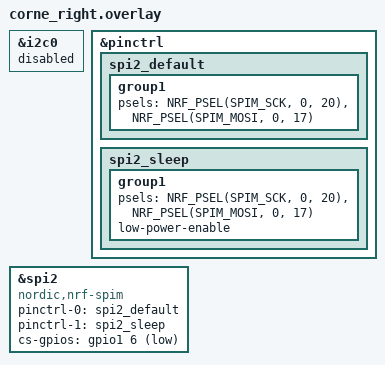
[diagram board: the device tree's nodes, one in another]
/*
 * nice!view en Corne con header OLED de 4 pines + CS directo a P1.06
 *
 * Pines del header OLED:
 *   MOSI  → P0.17  (SDA del OLED I2C original)
 *   SCK   → P0.20  (SCL del OLED I2C original)
 *
 * Cable extra soldado directamente al nice!nano:
 *   CS    → P1.06
 *
 * Usamos SPIM2 (spi2) — periférico independiente del hardware I2C0/TWIM0,
 * evita el conflicto "Only one of SPI0/TWI0 can be enabled".
 */

/* Deshabilitar I2C para liberar los pines P0.17 y P0.20 */
&i2c0 {
    status = "disabled";
};

&pinctrl {
    spi2_default: spi2_default {
        group1 {
            psels = <NRF_PSEL(SPIM_SCK, 0, 20)>,
                    <NRF_PSEL(SPIM_MOSI, 0, 17)>;
        };
    };

    spi2_sleep: spi2_sleep {
        group1 {
            psels = <NRF_PSEL(SPIM_SCK, 0, 20)>,
                    <NRF_PSEL(SPIM_MOSI, 0, 17)>;
            low-power-enable;
        };
    };
};

nice_view_spi: &spi2 {
    compatible = "nordic,nrf-spim";
    pinctrl-0 = <&spi2_default>;
    pinctrl-1 = <&spi2_sleep>;
    pinctrl-names = "default", "sleep";
    cs-gpios = <&gpio1 6 GPIO_ACTIVE_LOW>;
};
